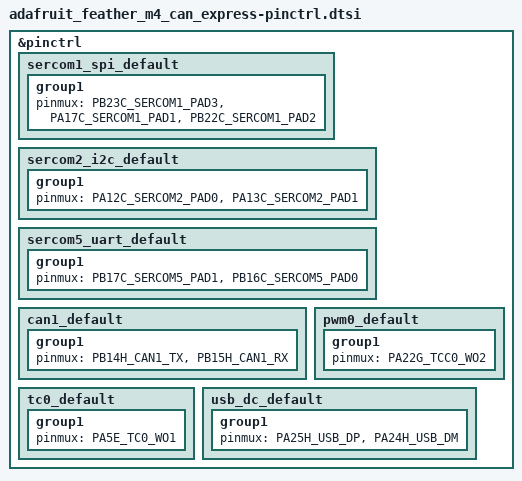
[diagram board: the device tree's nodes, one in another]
/*
 * Copyright (c) 2026 Frank Pagliughi
 *
 * SPDX-License-Identifier: Apache-2.0
 */

#include <dt-bindings/pinctrl/same51j-pinctrl.h>

&pinctrl {
	sercom1_spi_default: sercom1_spi_default {
		group1 {
			pinmux = <PB23C_SERCOM1_PAD3>,
				 <PA17C_SERCOM1_PAD1>,
				 <PB22C_SERCOM1_PAD2>;
		};
	};

	sercom2_i2c_default: sercom2_i2c_default {
		group1 {
			pinmux = <PA12C_SERCOM2_PAD0>,
				 <PA13C_SERCOM2_PAD1>;
		};
	};

	sercom5_uart_default: sercom5_uart_default {
		group1 {
			pinmux = <PB17C_SERCOM5_PAD1>,
				 <PB16C_SERCOM5_PAD0>;
		};
	};

	can1_default: can1_default {
		group1 {
			pinmux = <PB14H_CAN1_TX>,
				 <PB15H_CAN1_RX>;
		};
	};

	pwm0_default: pwm0_default {
		group1 {
			pinmux = <PA22G_TCC0_WO2>;
		};
	};

	tc0_default: tc0_default {
		group1 {
			pinmux = <PA5E_TC0_WO1>;
		};
	};

	usb_dc_default: usb_dc_default {
		group1 {
			pinmux = <PA25H_USB_DP>,
				 <PA24H_USB_DM>;
		};
	};
};
